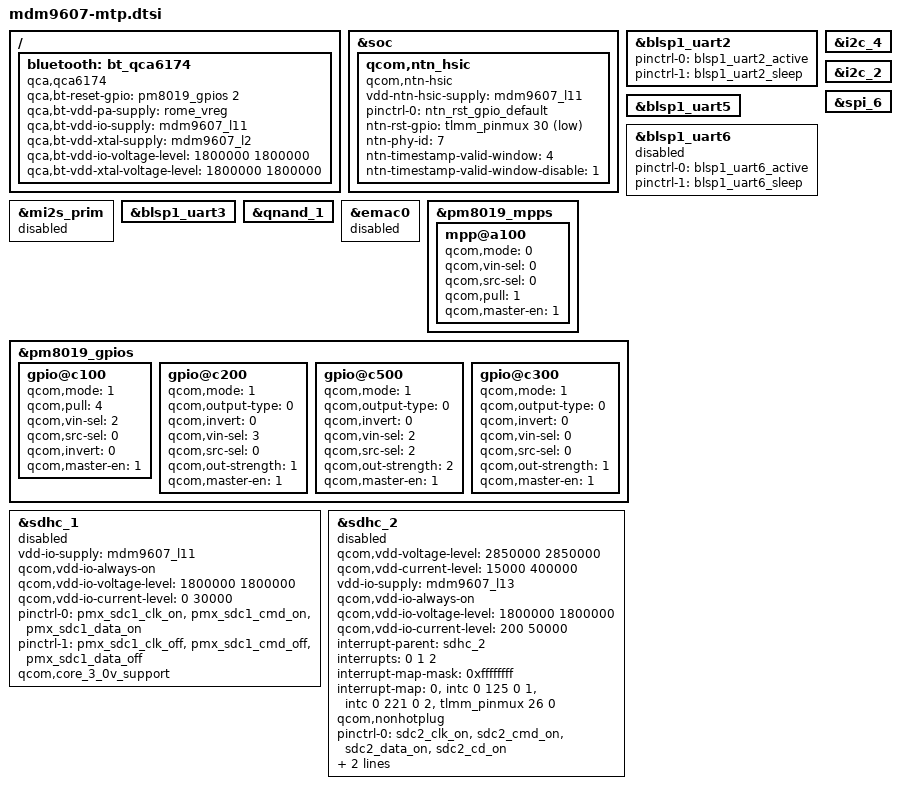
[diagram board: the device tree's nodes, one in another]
/*
 * Copyright (c) 2015-2017, The Linux Foundation. All rights reserved.
 *
 * This program is free software; you can redistribute it and/or modify
 * it under the terms of the GNU General Public License version 2 and
 * only version 2 as published by the Free Software Foundation.
 *
 * This program is distributed in the hope that it will be useful,
 * but WITHOUT ANY WARRANTY; without even the implied warranty of
 * MERCHANTABILITY or FITNESS FOR A PARTICULAR PURPOSE.  See the
 * GNU General Public License for more details.
 */

#include "mdm9607.dtsi"
#include "mdm9607-pinctrl.dtsi"

/ {
	bluetooth: bt_qca6174 {
		compatible = "qca,qca6174";
		qca,bt-reset-gpio = <&pm8019_gpios 2 0>; /* BT_EN */
		qca,bt-vdd-pa-supply = <&rome_vreg>;
		qca,bt-vdd-io-supply = <&mdm9607_l11>;
		qca,bt-vdd-xtal-supply = <&mdm9607_l2>;
		qca,bt-vdd-io-voltage-level = <1800000 1800000>;
		qca,bt-vdd-xtal-voltage-level = <1800000 1800000>;
	};
};

&soc {
	qcom,ntn_hsic {
		compatible = "qcom,ntn-hsic";
		vdd-ntn-hsic-supply = <&mdm9607_l11>;
		pinctrl-names = "default";
		pinctrl-0 = <&ntn_rst_gpio_default>;
		ntn-rst-gpio = <&tlmm_pinmux 30 1>;
		ntn-phy-id = <7>;
		ntn-timestamp-valid-window = <4>; /* Each unit is 16.75ms */
		ntn-timestamp-valid-window-disable = <1>; /* 1: To Disable */
	};

};
/* will.shao, add uart2 for debug uart*/
&blsp1_uart2 {
	status = "ok";
	pinctrl-names = "default","sleep";
	pinctrl-0 = <&blsp1_uart2_active>;
	pinctrl-1 = <&blsp1_uart2_sleep>;
};


/* larryzhang-20190225:The default is high speed for BLSP1_UART5(gpio8,9,10,11)*/
 &blsp1_uart5 {
 	status = "ok";
 };

/* UART6: enable gpio20, 21 uart6 by gale */
&blsp1_uart6 {
	status = "disabled";
	pinctrl-names = "default","sleep";
	pinctrl-0 = <&blsp1_uart6_active>;
	pinctrl-1 = <&blsp1_uart6_sleep>;
};

/* disable mi2s_pri gpio20,21,22,23 for enable uart6 by gale */
&mi2s_prim {
	status = "disabled";
};

&i2c_4 {
	status = "ok";
};

&i2c_2 {
	status = "ok";
};


//add by cullen
&spi_6 {
        status = "ok";
};

&blsp1_uart3 {
	status = "ok";
};

&qnand_1 {
	status = "ok";
};

&emac0 {
	status = "disabled";
};

//maxcodeflag20160329
/* MPP pin 2 configs for SMB358 interrupt line */
&pm8019_mpps {
	mpp@a100 {
		qcom,mode = <0>;	/* Digital input */
		qcom,vin-sel = <0>;	/*3: 1.8V (L11) */
		qcom,src-sel = <0>;	/* QPNP_PIN_SEL_FUNC_CONSTANT */
		/*qcom,pull = <2>; modified by max.tang for VBUS detect*/	/* PULL UP 10KOHM */
        qcom,pull = <1>;
		qcom,master-en = <1>;
        status = "ok";
	};
};

&pm8019_gpios {
	gpio@c100 { /* BT_EN */
		qcom,mode = <1>;         /* Digital output*/
		qcom,pull = <4>;         /* Pulldown 10uA */
		qcom,vin-sel = <2>;      /* VIN2 */
		qcom,src-sel = <0>;      /* GPIO */
		qcom,invert = <0>;       /* Invert */
		qcom,master-en = <1>;    /* Enable GPIO */
		status = "ok";
	};

	/* PMIC gpio for wlan power supply */
	gpio@c200 {
		qcom,mode = <1>;		/* Digital output */
		qcom,output-type = <0>;		/* CMOS logic */
		qcom,invert = <0>;		/* Output high */ /* carl.yin do not active PM_ENABLE_WIFI when bootup time, control by /etc/init.d/wlan */
		qcom,vin-sel = <3>;		/* VPH_PWR */
		qcom,src-sel = <0>;		/* Constant */
		qcom,out-strength = <1>;	/* High drive strength */
		qcom,master-en = <1>;		/* Enable GPIO */
		status = "okay";
	};

	/* ROME 32k Sleep Clock */
	gpio@c500 {
		qcom,mode = <1>;               /* Digital output */
		qcom,output-type = <0>;        /* CMOS logic */
		qcom,invert = <0>;             /* no inversion */
		qcom,vin-sel = <2>;            /* VIN 2 */
		qcom,src-sel = <2>;            /* Function 2 */
		qcom,out-strength = <2>;       /* Medium */
		qcom,master-en = <1>;          /* Enable GPIO */
		status = "ok";
	};
};

&sdhc_1 {
	vdd-io-supply = <&mdm9607_l11>;
	qcom,vdd-io-always-on;
	qcom,vdd-io-voltage-level = <1800000 1800000>;
	qcom,vdd-io-current-level = <0 30000>;

	pinctrl-names = "active", "sleep";
	pinctrl-0 = <&pmx_sdc1_clk_on &pmx_sdc1_cmd_on &pmx_sdc1_data_on
						/*&sdc1_wlan_gpio_active*/>; /*edison.yang /sys/class/gpio/gpio54*/
	pinctrl-1 = <&pmx_sdc1_clk_off &pmx_sdc1_cmd_off &pmx_sdc1_data_off
						/*&sdc1_wlan_gpio_sleep*/>;
	/* qcom,nonremovable; */
	qcom,core_3_0v_support;
	status = "disabled";
};

&pm8019_gpios {
	gpio@c300 { /* GPIO 4 */
		qcom,mode = <1>;		/* Digital output */
		qcom,output-type = <0>;		/* CMOS logic */
		qcom,invert = <0>;		/* Output high */
		qcom,vin-sel = <0>;		/* VPH_PWR */
		qcom,src-sel = <0>;		/* GPIO */
		qcom,out-strength = <1>;	/* Low drive strength */
		qcom,master-en = <1>;		/* Enable GPIO */
	};
};

/* MPP pin 4 configs for SGMII */
&pm8019_mpps {
	//mpp@a300 { /* MPP 4 */
	//	qcom,mode = <1>;		/* Digital output */
	//	qcom,vin-sel = <2>;		/* 1.8V */
	//	qcom,src-sel = <0>;		/* Constant */
	//	qcom,master-en = <1>;		/* Enable GPIO */
	//	status = "disabled";		/* modify by gale 2017-08-22, MPP4 for adc function */
	//};
};


&sdhc_2 {
	/*vdd-supply = <&sdcard_ext_vreg>;*/
	qcom,vdd-voltage-level = <2850000 2850000>;
	qcom,vdd-current-level = <15000 400000>;

	vdd-io-supply = <&mdm9607_l13>;
	qcom,vdd-io-always-on;                  //20170915,add by cullen
	qcom,vdd-io-voltage-level = <1800000 1800000>;
	qcom,vdd-io-current-level = <200 50000>;

	#address-cells = <0>;
	interrupt-parent = <&sdhc_2>;
	interrupts = <0 1 2>;
	#interrupt-cells = <1>;
	interrupt-map-mask = <0xffffffff>;
	interrupt-map = <0 &intc 0 125 0
			1 &intc 0 221 0
			2 &tlmm_pinmux 26 0>;
	interrupt-names = "hc_irq", "pwr_irq", "status_irq";
   	/*cd-gpios = <&tlmm_pinmux 26 0x1>;*/
 	qcom,nonhotplug;
	pinctrl-names = "active", "sleep";
	pinctrl-0 = <&sdc2_clk_on &sdc2_cmd_on &sdc2_data_on &sdc2_cd_on>;
	pinctrl-1 = <&sdc2_clk_off &sdc2_cmd_off &sdc2_data_off>;

	status = "disabled";
};
